AUTOSAR XML (schema 00051)
package /Components
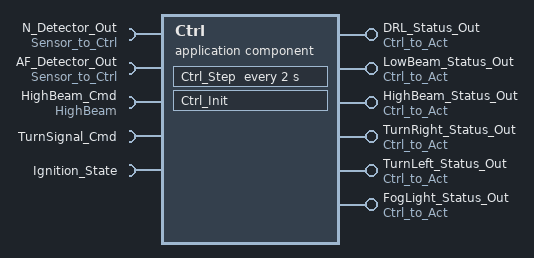
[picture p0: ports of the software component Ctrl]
  application sw component type Ctrl
    5 x require port, all with nonqueued-receiver-com-spec{data-element=Value, init-value=0}:
      N_Detector_Out: required-interface=Sensor_to_Ctrl
      AF_Detector_Out: required-interface=Sensor_to_Ctrl
      HighBeam_Cmd: required-interface=HighBeam
      TurnSignal_Cmd: required-interface=TurnSignal_Cmd
      Ignition_State: required-interface=Ignition_State
    6 x provide port, all with nonqueued-sender-com-spec{data-element=Value, init-value=0}, provided-interface=Ctrl_to_Act:
      DRL_Status_Out
      LowBeam_Status_Out
      HighBeam_Status_Out
      TurnRight_Status_Out
      TurnLeft_Status_Out
      FogLight_Status_Out
    behavior Ctrl_IB: data-type-mapping=dictDataTypeMappingsSet, handle-termination-and-restart=NO-SUPPORT
      timing event Event_Ctrl_Step: start-on-event=Ctrl_Step, period=2
      runnable Ctrl_Init
      runnable Ctrl_Step
        data-read-access:
          5 x access:
            IN_Ignition_State_Value: accessed-variable=Ignition_State.Value
            IN_N_Detector_Out_Value: accessed-variable=N_Detector_Out.Value
            IN_AF_Detector_Out_Value: accessed-variable=AF_Detector_Out.Value
            IN_TurnSignal_Cmd_Value: accessed-variable=TurnSignal_Cmd.Value
            IN_HighBeam_Cmd_Value: accessed-variable=HighBeam_Cmd.Value
        data-write-access:
          6 x access:
            OUT_DRL_Status_Out_Value: accessed-variable=DRL_Status_Out.Value
            OUT_LowBeam_Status_Out_Value: accessed-variable=LowBeam_Status_Out.Value
            OUT_HighBeam_Status_Out_Value: accessed-variable=HighBeam_Status_Out.Value
            OUT_TurnRight_Status_Out_Value: accessed-variable=TurnRight_Status_Out.Value
            OUT_TurnLeft_Status_Out_Value: accessed-variable=TurnLeft_Status_Out.Value
            OUT_FogLight_Status_Out_Value: accessed-variable=FogLight_Status_Out.Value
